# examp_regs: IP-XACT component
VLNV example.org:mylibrary:examp_regs:1.0

## Address spaces and blocks
examp_regs_mmap.examp_regs: base 'h0, range 'h20, width 32

## Registers
Registers are 32-bit, read-only, reset 0x0 unless marked. A register's access mark holds for its fields unless they carry their own. Offsets are from the block's base; lines under a group give offsets from that group; [hi:lo] are bit positions; {n}, {i} and the like mark numbered series; 'fields as' and 'values as' point back to an identical list; <NAME> marks a mode.

## examp_regs_mmap.examp_regs — Example register description.
Base 0x00000000
0x00 scratchpad rw — Scratchpad register for FPGA firmware testing.
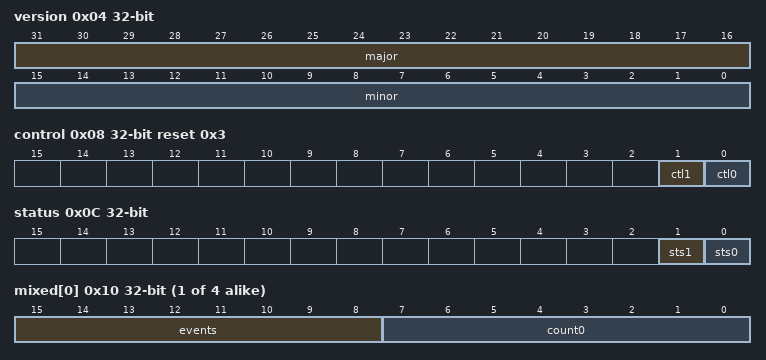
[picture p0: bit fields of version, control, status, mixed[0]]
0x04 version reset not defined — Read-only FPGA version register. A new version here indicates that the FPGA HDL has changed in some meaningful way.
  [31:16] major, [15:0] minor
0x08 control rw reset 0x3 — Overall control register.
  [1] ctl1 — Control 1
  [0] ctl0 — Control 0
0x0C status reset not defined — Overall status register.
  [1] sts1 — Status 1
  [0] sts0 — Status 0
{0x10+4i} mixed[{i}] (i=0..3) — Mixed register with loads of functionality.
  [15:8] events read-clears — Description of events register.
  [7:0] count0 — Incrementing Count Register
